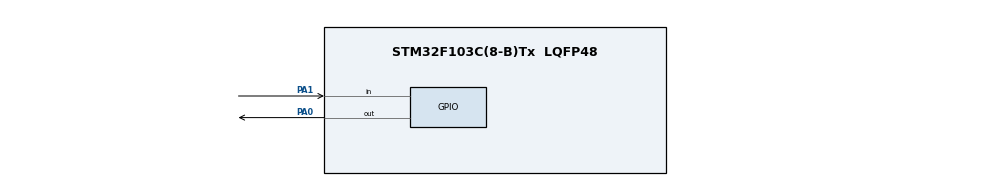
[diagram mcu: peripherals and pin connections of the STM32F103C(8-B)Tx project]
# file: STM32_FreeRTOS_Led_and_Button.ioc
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FREERTOS.Tasks01=defaultTask,24,128,StartDefaultTask,Default,NULL,Dynamic,NULL,NULL
Mcu.Family=STM32F1
Mcu.Name=STM32F103C(8-B)Tx
Mcu.Package=LQFP48
NVIC.PriorityGroup=NVIC_PRIORITYGROUP_4
NVIC.TIM1_UP_IRQn=true\:0\:0\:false\:false\:true\:false\:false\:true
NVIC.TimeBase=TIM1_UP_IRQn
NVIC.TimeBaseIP=TIM1
PA0-WKUP.Signal=GPIO_Output
PA1.GPIO_PuPd=GPIO_PULLUP
PA1.Signal=GPIO_Input
PA13.Mode=Serial_Wire
PA13.Signal=SYS_JTMS-SWDIO
PA14.Mode=Serial_Wire
PA14.Signal=SYS_JTCK-SWCLK
PC14-OSC32_IN.Mode=LSE-External-Oscillator
PC14-OSC32_IN.Signal=RCC_OSC32_IN
PC15-OSC32_OUT.Mode=LSE-External-Oscillator
PC15-OSC32_OUT.Signal=RCC_OSC32_OUT
PD0-OSC_IN.Mode=HSE-External-Oscillator
PD0-OSC_IN.Signal=RCC_OSC_IN
PD1-OSC_OUT.Mode=HSE-External-Oscillator
PD1-OSC_OUT.Signal=RCC_OSC_OUT
ProjectManager.HeapSize=0x200
ProjectManager.StackSize=0x400
ProjectManager.TargetToolchain=TrueSTUDIO
RCC.APB1Freq_Value=8000000
RCC.APB2Freq_Value=8000000
VP_FREERTOS_VS_CMSIS_V2.Mode=CMSIS_V2
VP_SYS_VS_tim1.Mode=TIM1
board=custom

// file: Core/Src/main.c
/* USER CODE BEGIN Header */
/**
  ******************************************************************************
  * @file           : main.c
  * @brief          : Main program body
  ******************************************************************************
  * @attention
  *
  * <h2><center>&copy; Copyright (c) 2020 STMicroelectronics.
  * All rights reserved.</center></h2>
  *
  * This software component is licensed by ST under Ultimate Liberty license
  * SLA0044, the "License"; You may not use this file except in compliance with
  * the License. You may obtain a copy of the License at:
  *                             www.st.com/SLA0044
  *
  ******************************************************************************
  */
/* USER CODE END Header */
#include "main.h"
#include "cmsis_os.h"

/* USER CODE BEGIN PD */
#define TRUE				1
#define FALSE				0
#define PRESSED				TRUE
#define NOT_PRESSED			FALSE
/* USER CODE END PD */

/* USER CODE BEGIN PV */
uint8_t button_status_flag = NOT_PRESSED;
/* USER CODE END PV */

void SystemClock_Config(void);
static void MX_GPIO_Init(void);

/* USER CODE BEGIN PFP */
void led_task_handler(void *params);
void button_task_handler(void *params);
/* USER CODE END PFP */

int main(void)
{

  /* MCU Configuration--------------------------------------------------------*/

  /* Reset of all peripherals, Initializes the Flash interface and the Systick. */
  HAL_Init();

  /* USER CODE BEGIN Init */
  HAL_GPIO_WritePin(GPIOA, GPIO_PIN_0, 0);
  /* USER CODE END Init */

  /* Configure the system clock */
  SystemClock_Config();

  /* Initialize all configured peripherals */
  MX_GPIO_Init();

  /* Init scheduler */
  osKernelInitialize();

  /* Create the thread(s) */
  /* creation of defaultTask */

  //Led task
  xTaskCreate( led_task_handler,"LED-Task",configMINIMAL_STACK_SIZE,NULL,1 ,NULL);

  //Button task
  xTaskCreate( button_task_handler,"BUTTON-Task",configMINIMAL_STACK_SIZE,NULL,1 ,NULL);

  /* Start scheduler */
  vTaskStartScheduler();

  /* We should never get here as control is now taken by the scheduler */
  /* Infinite loop */
  while (1)
  {

  }
}

void SystemClock_Config(void)
{
  RCC_OscInitTypeDef RCC_OscInitStruct = {0};
  RCC_ClkInitTypeDef RCC_ClkInitStruct = {0};

  /** Initializes the RCC Oscillators according to the specified parameters
  * in the RCC_OscInitTypeDef structure.
  */
  RCC_OscInitStruct.OscillatorType = RCC_OSCILLATORTYPE_HSI;
  RCC_OscInitStruct.HSIState = RCC_HSI_ON;
  RCC_OscInitStruct.HSICalibrationValue = RCC_HSICALIBRATION_DEFAULT;
  RCC_OscInitStruct.PLL.PLLState = RCC_PLL_NONE;
  if (HAL_RCC_OscConfig(&RCC_OscInitStruct) != HAL_OK)
  {
    Error_Handler();
  }
  /** Initializes the CPU, AHB and APB buses clocks
  */
  RCC_ClkInitStruct.ClockType = RCC_CLOCKTYPE_HCLK|RCC_CLOCKTYPE_SYSCLK
                              |RCC_CLOCKTYPE_PCLK1|RCC_CLOCKTYPE_PCLK2;
  RCC_ClkInitStruct.SYSCLKSource = RCC_SYSCLKSOURCE_HSI;
  RCC_ClkInitStruct.AHBCLKDivider = RCC_SYSCLK_DIV1;
  RCC_ClkInitStruct.APB1CLKDivider = RCC_HCLK_DIV1;
  RCC_ClkInitStruct.APB2CLKDivider = RCC_HCLK_DIV1;

  if (HAL_RCC_ClockConfig(&RCC_ClkInitStruct, FLASH_LATENCY_0) != HAL_OK)
  {
    Error_Handler();
  }
}

static void MX_GPIO_Init(void)
{
  GPIO_InitTypeDef GPIO_InitStruct = {0};

  /* GPIO Ports Clock Enable */
  __HAL_RCC_GPIOC_CLK_ENABLE();
  __HAL_RCC_GPIOD_CLK_ENABLE();
  __HAL_RCC_GPIOA_CLK_ENABLE();

  /*Configure GPIO pin Output Level */
  HAL_GPIO_WritePin(GPIOA, GPIO_PIN_0, GPIO_PIN_RESET);

  /*Configure GPIO pin : PA0 */
  GPIO_InitStruct.Pin = GPIO_PIN_0;
  GPIO_InitStruct.Mode = GPIO_MODE_OUTPUT_PP;
  GPIO_InitStruct.Pull = GPIO_NOPULL;
  GPIO_InitStruct.Speed = GPIO_SPEED_FREQ_LOW;
  HAL_GPIO_Init(GPIOA, &GPIO_InitStruct);

  /*Configure GPIO pin : PA1 */
  GPIO_InitStruct.Pin = GPIO_PIN_1;
  GPIO_InitStruct.Mode = GPIO_MODE_INPUT;
  GPIO_InitStruct.Pull = GPIO_PULLUP;
  HAL_GPIO_Init(GPIOA, &GPIO_InitStruct);

}

/* USER CODE BEGIN 4 */

/**
  * @brief Turn led off or on
  * @retval None
  */
void led_task_handler(void *params)
{

	while(1)
	{
		if(button_status_flag == PRESSED)
			HAL_GPIO_WritePin(GPIOA, GPIO_PIN_0, 1);
		else
			HAL_GPIO_WritePin(GPIOA, GPIO_PIN_0, 0);
	}
}

/**
  * @brief poll the button status and if pressed should update the flag variable
  * @retval None
  */
void button_task_handler(void *params)
{

	while(1)
	{
		if(HAL_GPIO_ReadPin(GPIOA, GPIO_PIN_1) == 0)
		{
			button_status_flag = PRESSED;
		}
		else
		{
			button_status_flag = NOT_PRESSED;
		}
	}
}

/* USER CODE END 4 */

void HAL_TIM_PeriodElapsedCallback(TIM_HandleTypeDef *htim)
{
  if (htim->Instance == TIM1) {
    HAL_IncTick();
  }
}

void Error_Handler(void)
{
}

/************************ (C) COPYRIGHT STMicroelectronics *****END OF FILE****/
